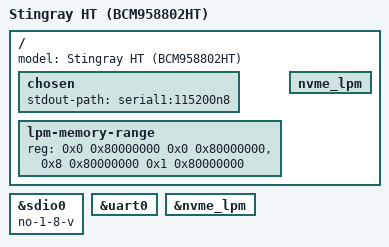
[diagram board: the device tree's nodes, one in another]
// SPDX-License-Identifier: (GPL-2.0 or BSD-3-Clause)
/*
 *  Copyright(c) 2018 Broadcom
 */

/dts-v1/;

#define NUM_CRYPTO	32
#define NUM_RAID	0
#define ENABLE_DMC0	1
#define ENABLE_DMC2	1
#define ENABLE_ENET	0
#define ENABLE_MDIO	0
#define ENABLE_USB1	0

#define ENABLE_I2C0	1

#define ENABLE_IHOST12_CPUS 0

#include "../../stingray-board-base.dtsi"

/ {
	model = "Stingray HT (BCM958802HT)";

	chosen {
		stdout-path = "serial1:115200n8";
	};

	lpm-memory-range {
		reg = <0x0 0x80000000 0x0 0x80000000>, /* 2G @ 2G */
		      <0x8 0x80000000 0x1 0x80000000>; /* 6G @ 34G */
	};

	nvme_lpm {
		status = "okay";
	};
};

&sdio0 {
	no-1-8-v;
};

&uart0 {
	status = "okay";
};

&nvme_lpm {
	status = "okay";
};
